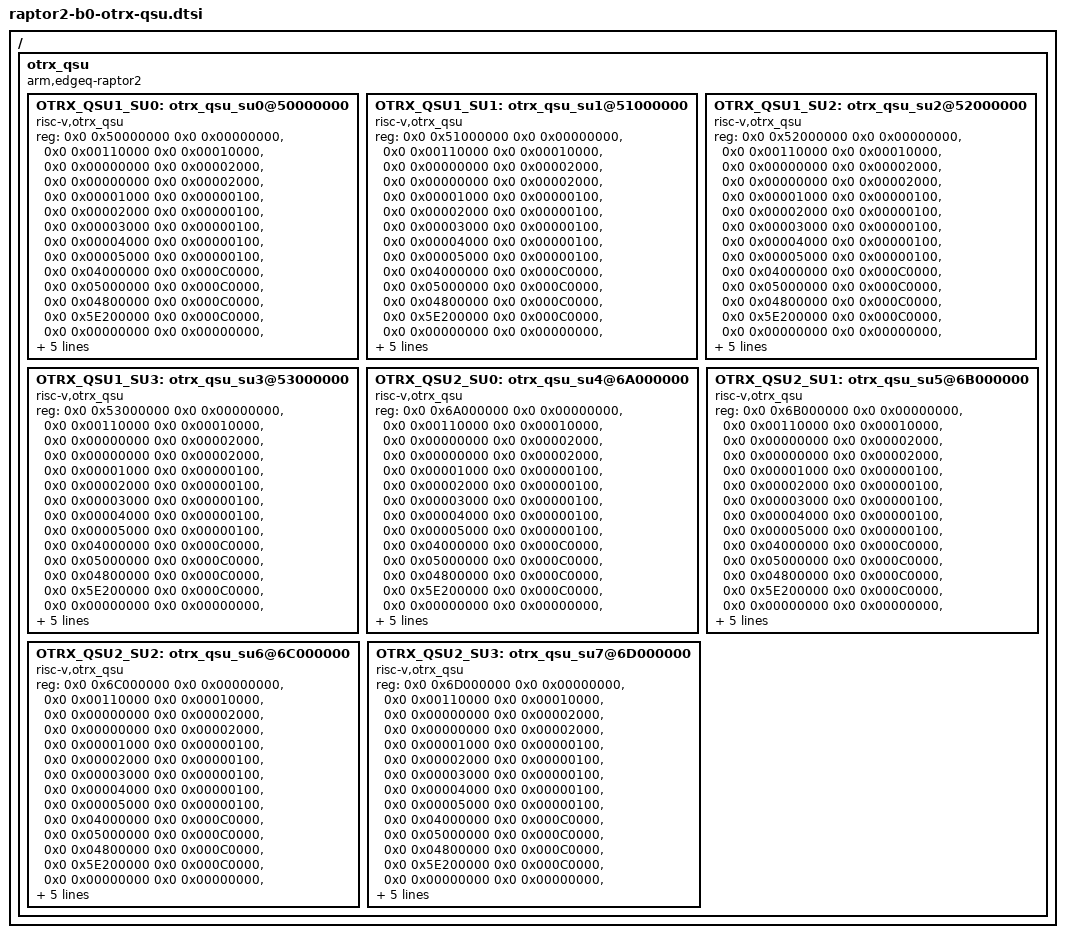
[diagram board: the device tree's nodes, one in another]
// SPDX-License-Identifier: GPL-2.0
/*
 * EdgeQ Inc.
 *
 * EdgeQ Raptor2 OTRX_QSU DTS
 */

/ {

	otrx_qsu {
		compatible = "arm,edgeq-raptor2";
		#address-cells = <2>;
		#size-cells = <2>;

		OTRX_QSU1_SU0: otrx_qsu_su0@50000000 {
			compatible = "risc-v,otrx_qsu";
			device_type = "su";
			#address-cells = <2>;
			#size-cells = <2>;
			ranges;
			reg =	<0x0 0x50000000 0x0 0x00000000>,
				<0x0 0x00110000 0x0 0x00010000>,
				<0x0 0x00000000 0x0 0x00002000>,
				<0x0 0x00000000 0x0 0x00002000>,
				<0x0 0x00001000 0x0 0x00000100>,
				<0x0 0x00002000 0x0 0x00000100>,
				<0x0 0x00003000 0x0 0x00000100>,
				<0x0 0x00004000 0x0 0x00000100>,
				<0x0 0x00005000 0x0 0x00000100>,
				<0x0 0x04000000 0x0 0x000C0000>,
				<0x0 0x05000000 0x0 0x000C0000>,
				<0x0 0x04800000 0x0 0x000C0000>,
				<0x0 0x5E200000 0x0 0x000C0000>,
				<0x0 0x00000000 0x0 0x00000000>,
				<0x0 0x00000000 0x0 0x00010000>,
				<0x0 0x00080000 0x0 0x00008000>;
			reg-names = "sudev_base", "cpu", "d-cache", "i-cache", "suinfo_offset",
				"suconf_offset", "suau_offset", "sustats_offset", "sudbg_offset",
				"lmem_addr_local_wb", "lmem_addr_local_unc", "lmem_addr_local_wt",
				"lmem_e1", "lmem_e1_b2", "ilmoffs", "dlmoffs";
			enable-method = "reset-vector";
			sudev = <&SUDEV>;
			sumem = <&SUMEM>;
			status = "okay";
		};

		OTRX_QSU1_SU1: otrx_qsu_su1@51000000 {
			compatible = "risc-v,otrx_qsu";
			device_type = "su";
			#address-cells = <2>;
			#size-cells = <2>;
			ranges;
			reg =	<0x0 0x51000000 0x0 0x00000000>,
				<0x0 0x00110000 0x0 0x00010000>,
				<0x0 0x00000000 0x0 0x00002000>,
				<0x0 0x00000000 0x0 0x00002000>,
				<0x0 0x00001000 0x0 0x00000100>,
				<0x0 0x00002000 0x0 0x00000100>,
				<0x0 0x00003000 0x0 0x00000100>,
				<0x0 0x00004000 0x0 0x00000100>,
				<0x0 0x00005000 0x0 0x00000100>,
				<0x0 0x04000000 0x0 0x000C0000>,
				<0x0 0x05000000 0x0 0x000C0000>,
				<0x0 0x04800000 0x0 0x000C0000>,
				<0x0 0x5E200000 0x0 0x000C0000>,
				<0x0 0x00000000 0x0 0x00000000>,
				<0x0 0x00000000 0x0 0x00010000>,
				<0x0 0x00080000 0x0 0x00008000>;
			reg-names = "sudev_base", "cpu", "d-cache", "i-cache", "suinfo_offset",
				"suconf_offset", "suau_offset", "sustats_offset", "sudbg_offset",
				"lmem_addr_local_wb", "lmem_addr_local_unc", "lmem_addr_local_wt",
				"lmem_e1", "lmem_e1_b2", "ilmoffs", "dlmoffs";
			enable-method = "reset-vector";
			sudev = <&SUDEV>;
			sumem = <&SUMEM>;
			status = "okay";
		};

		OTRX_QSU1_SU2: otrx_qsu_su2@52000000 {
			compatible = "risc-v,otrx_qsu";
			device_type = "su";
			#address-cells = <2>;
			#size-cells = <2>;
			ranges;
			reg =	<0x0 0x52000000 0x0 0x00000000>,
				<0x0 0x00110000 0x0 0x00010000>,
				<0x0 0x00000000 0x0 0x00002000>,
				<0x0 0x00000000 0x0 0x00002000>,
				<0x0 0x00001000 0x0 0x00000100>,
				<0x0 0x00002000 0x0 0x00000100>,
				<0x0 0x00003000 0x0 0x00000100>,
				<0x0 0x00004000 0x0 0x00000100>,
				<0x0 0x00005000 0x0 0x00000100>,
				<0x0 0x04000000 0x0 0x000C0000>,
				<0x0 0x05000000 0x0 0x000C0000>,
				<0x0 0x04800000 0x0 0x000C0000>,
				<0x0 0x5E200000 0x0 0x000C0000>,
				<0x0 0x00000000 0x0 0x00000000>,
				<0x0 0x00000000 0x0 0x00010000>,
				<0x0 0x00080000 0x0 0x00008000>;
			reg-names = "sudev_base", "cpu", "d-cache", "i-cache", "suinfo_offset",
				"suconf_offset", "suau_offset", "sustats_offset", "sudbg_offset",
				"lmem_addr_local_wb", "lmem_addr_local_unc", "lmem_addr_local_wt",
				"lmem_e1", "lmem_e1_b2", "ilmoffs", "dlmoffs";
			enable-method = "reset-vector";
			sudev = <&SUDEV>;
			sumem = <&SUMEM>;
			status = "okay";
		};

		OTRX_QSU1_SU3: otrx_qsu_su3@53000000 {
			compatible = "risc-v,otrx_qsu";
			device_type = "su";
			#address-cells = <2>;
			#size-cells = <2>;
			ranges;
			reg =	<0x0 0x53000000 0x0 0x00000000>,
				<0x0 0x00110000 0x0 0x00010000>,
				<0x0 0x00000000 0x0 0x00002000>,
				<0x0 0x00000000 0x0 0x00002000>,
				<0x0 0x00001000 0x0 0x00000100>,
				<0x0 0x00002000 0x0 0x00000100>,
				<0x0 0x00003000 0x0 0x00000100>,
				<0x0 0x00004000 0x0 0x00000100>,
				<0x0 0x00005000 0x0 0x00000100>,
				<0x0 0x04000000 0x0 0x000C0000>,
				<0x0 0x05000000 0x0 0x000C0000>,
				<0x0 0x04800000 0x0 0x000C0000>,
				<0x0 0x5E200000 0x0 0x000C0000>,
				<0x0 0x00000000 0x0 0x00000000>,
				<0x0 0x00000000 0x0 0x00010000>,
				<0x0 0x00080000 0x0 0x00008000>;
			reg-names = "sudev_base", "cpu", "d-cache", "i-cache", "suinfo_offset",
				"suconf_offset", "suau_offset", "sustats_offset", "sudbg_offset",
				"lmem_addr_local_wb", "lmem_addr_local_unc", "lmem_addr_local_wt",
				"lmem_e1", "lmem_e1_b2", "ilmoffs", "dlmoffs";
			enable-method = "reset-vector";
			sudev = <&SUDEV>;
			sumem = <&SUMEM>;
			status = "okay";
		};

		OTRX_QSU2_SU0: otrx_qsu_su4@6A000000 {
			compatible = "risc-v,otrx_qsu";
			device_type = "su";
			#address-cells = <2>;
			#size-cells = <2>;
			ranges;
			reg =	<0x0 0x6A000000 0x0 0x00000000>,
				<0x0 0x00110000 0x0 0x00010000>,
				<0x0 0x00000000 0x0 0x00002000>,
				<0x0 0x00000000 0x0 0x00002000>,
				<0x0 0x00001000 0x0 0x00000100>,
				<0x0 0x00002000 0x0 0x00000100>,
				<0x0 0x00003000 0x0 0x00000100>,
				<0x0 0x00004000 0x0 0x00000100>,
				<0x0 0x00005000 0x0 0x00000100>,
				<0x0 0x04000000 0x0 0x000C0000>,
				<0x0 0x05000000 0x0 0x000C0000>,
				<0x0 0x04800000 0x0 0x000C0000>,
				<0x0 0x5E200000 0x0 0x000C0000>,
				<0x0 0x00000000 0x0 0x00000000>,
				<0x0 0x00000000 0x0 0x00010000>,
				<0x0 0x00080000 0x0 0x00010000>;
			reg-names = "sudev_base", "cpu", "d-cache", "i-cache", "suinfo_offset",
				"suconf_offset", "suau_offset", "sustats_offset", "sudbg_offset",
				"lmem_addr_local_wb", "lmem_addr_local_unc", "lmem_addr_local_wt",
				"lmem_e1", "lmem_e1_b2", "ilmoffs", "dlmoffs";
			enable-method = "reset-vector";
			sudev = <&SUDEV>;
			sumem = <&SUMEM>;
			status = "okay";
		};

		OTRX_QSU2_SU1: otrx_qsu_su5@6B000000 {
			compatible = "risc-v,otrx_qsu";
			device_type = "su";
			#address-cells = <2>;
			#size-cells = <2>;
			ranges;
			reg =	<0x0 0x6B000000 0x0 0x00000000>,
				<0x0 0x00110000 0x0 0x00010000>,
				<0x0 0x00000000 0x0 0x00002000>,
				<0x0 0x00000000 0x0 0x00002000>,
				<0x0 0x00001000 0x0 0x00000100>,
				<0x0 0x00002000 0x0 0x00000100>,
				<0x0 0x00003000 0x0 0x00000100>,
				<0x0 0x00004000 0x0 0x00000100>,
				<0x0 0x00005000 0x0 0x00000100>,
				<0x0 0x04000000 0x0 0x000C0000>,
				<0x0 0x05000000 0x0 0x000C0000>,
				<0x0 0x04800000 0x0 0x000C0000>,
				<0x0 0x5E200000 0x0 0x000C0000>,
				<0x0 0x00000000 0x0 0x00000000>,
				<0x0 0x00000000 0x0 0x00010000>,
				<0x0 0x00080000 0x0 0x00010000>;
			reg-names = "sudev_base", "cpu", "d-cache", "i-cache", "suinfo_offset",
				"suconf_offset", "suau_offset", "sustats_offset", "sudbg_offset",
				"lmem_addr_local_wb", "lmem_addr_local_unc", "lmem_addr_local_wt",
				"lmem_e1", "lmem_e1_b2", "ilmoffs", "dlmoffs";
			enable-method = "reset-vector";
			sudev = <&SUDEV>;
			sumem = <&SUMEM>;
			status = "okay";
		};

		OTRX_QSU2_SU2: otrx_qsu_su6@6C000000 {
			compatible = "risc-v,otrx_qsu";
			device_type = "su";
			#address-cells = <2>;
			#size-cells = <2>;
			ranges;
			reg =	<0x0 0x6C000000 0x0 0x00000000>,
				<0x0 0x00110000 0x0 0x00010000>,
				<0x0 0x00000000 0x0 0x00002000>,
				<0x0 0x00000000 0x0 0x00002000>,
				<0x0 0x00001000 0x0 0x00000100>,
				<0x0 0x00002000 0x0 0x00000100>,
				<0x0 0x00003000 0x0 0x00000100>,
				<0x0 0x00004000 0x0 0x00000100>,
				<0x0 0x00005000 0x0 0x00000100>,
				<0x0 0x04000000 0x0 0x000C0000>,
				<0x0 0x05000000 0x0 0x000C0000>,
				<0x0 0x04800000 0x0 0x000C0000>,
				<0x0 0x5E200000 0x0 0x000C0000>,
				<0x0 0x00000000 0x0 0x00000000>,
				<0x0 0x00000000 0x0 0x00010000>,
				<0x0 0x00080000 0x0 0x00010000>;
			reg-names = "sudev_base", "cpu", "d-cache", "i-cache", "suinfo_offset",
				"suconf_offset", "suau_offset", "sustats_offset", "sudbg_offset",
				"lmem_addr_local_wb", "lmem_addr_local_unc", "lmem_addr_local_wt",
				"lmem_e1", "lmem_e1_b2", "ilmoffs", "dlmoffs";
			enable-method = "reset-vector";
			sudev = <&SUDEV>;
			sumem = <&SUMEM>;
			status = "okay";
		};

		OTRX_QSU2_SU3: otrx_qsu_su7@6D000000 {
			compatible = "risc-v,otrx_qsu";
			device_type = "su";
			#address-cells = <2>;
			#size-cells = <2>;
			ranges;
			reg =	<0x0 0x6D000000 0x0 0x00000000>,
				<0x0 0x00110000 0x0 0x00010000>,
				<0x0 0x00000000 0x0 0x00002000>,
				<0x0 0x00000000 0x0 0x00002000>,
				<0x0 0x00001000 0x0 0x00000100>,
				<0x0 0x00002000 0x0 0x00000100>,
				<0x0 0x00003000 0x0 0x00000100>,
				<0x0 0x00004000 0x0 0x00000100>,
				<0x0 0x00005000 0x0 0x00000100>,
				<0x0 0x04000000 0x0 0x000C0000>,
				<0x0 0x05000000 0x0 0x000C0000>,
				<0x0 0x04800000 0x0 0x000C0000>,
				<0x0 0x5E200000 0x0 0x000C0000>,
				<0x0 0x00000000 0x0 0x00000000>,
				<0x0 0x00000000 0x0 0x00010000>,
				<0x0 0x00080000 0x0 0x00010000>;
			reg-names = "sudev_base", "cpu", "d-cache", "i-cache", "suinfo_offset",
				"suconf_offset", "suau_offset", "sustats_offset", "sudbg_offset",
				"lmem_addr_local_wb", "lmem_addr_local_unc", "lmem_addr_local_wt",
				"lmem_e1", "lmem_e1_b2", "ilmoffs", "dlmoffs";
			enable-method = "reset-vector";
			sudev = <&SUDEV>;
			sumem = <&SUMEM>;
			status = "okay";
		};
	};
};
